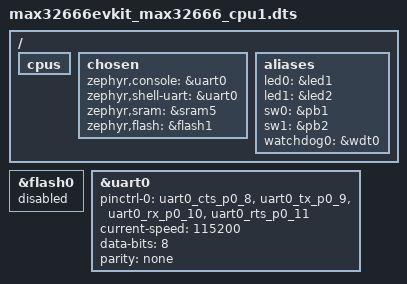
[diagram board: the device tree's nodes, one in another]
/*
 * Copyright (c) 2024 Analog Devices, Inc.
 *
 * SPDX-License-Identifier: Apache-2.0
 */

#include "max32666evkit.dtsi"

&flash0 {
	status = "disabled";
};

/ {
	cpus {
		/delete-node/ cpu@0;
	};

	chosen {
		zephyr,console = &uart0;
		zephyr,shell-uart = &uart0;
		zephyr,sram = &sram5;
		zephyr,flash = &flash1;
	};

	/* These aliases are provided for compatibility with samples */
	aliases {
		led0 = &led1;
		led1 = &led2;
		sw0 = &pb1;
		sw1 = &pb2;
		watchdog0 = &wdt0;
	};
};

&uart0 {
	pinctrl-0 = <&uart0_cts_p0_8 &uart0_tx_p0_9 &uart0_rx_p0_10 &uart0_rts_p0_11>;
	pinctrl-names = "default";
	current-speed = <115200>;
	data-bits = <8>;
	parity = "none";
	status = "okay";
};
